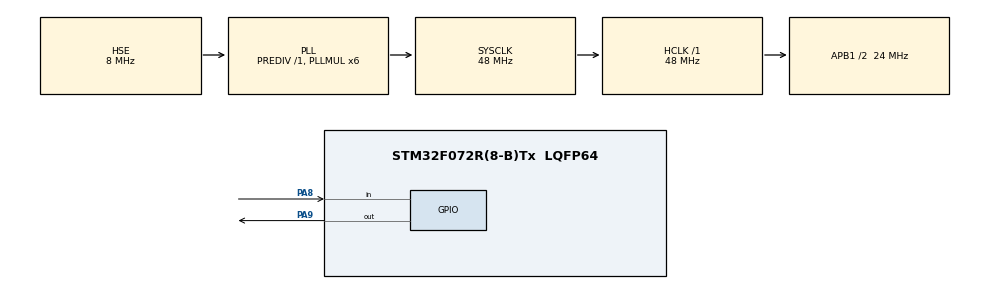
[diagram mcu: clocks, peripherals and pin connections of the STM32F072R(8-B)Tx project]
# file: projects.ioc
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Mcu.Family=STM32F0
Mcu.Name=STM32F072R(8-B)Tx
Mcu.Package=LQFP64
PA13.Mode=Serial_Wire
PA13.Signal=SYS_SWDIO
PA14.Mode=Serial_Wire
PA14.Signal=SYS_SWCLK
PA8.Signal=GPIO_Input
PA9.Signal=GPIO_Output
PF0-OSC_IN.Mode=HSE-External-Oscillator
PF0-OSC_IN.Signal=RCC_OSC_IN
PF1-OSC_OUT.Mode=HSE-External-Oscillator
PF1-OSC_OUT.Signal=RCC_OSC_OUT
ProjectManager.HeapSize=0x200
ProjectManager.StackSize=0x400
ProjectManager.TargetToolchain=MDK-ARM V5.32
RCC.AHBFreq_Value=48000000
RCC.APB1CLKDivider=RCC_HCLK_DIV2
RCC.APB1Freq_Value=24000000
RCC.APB1TimFreq_Value=48000000
RCC.HCLKFreq_Value=48000000
RCC.PLLMUL=RCC_PLL_MUL6
RCC.PLLSourceVirtual=RCC_PLLSOURCE_HSE
RCC.SYSCLKFreq_VALUE=48000000
RCC.SYSCLKSource=RCC_SYSCLKSOURCE_PLLCLK
TIM1.Prescaler=47
VP_TIM1_VS_ClockSourceINT.Mode=Internal
board=custom

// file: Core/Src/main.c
/* USER CODE BEGIN Header */
/**
  ******************************************************************************
  * @file           : main.c
  * @brief          : Main program body
  ******************************************************************************
  * @attention
  *
  * Copyright (c) 2024 STMicroelectronics.
  * All rights reserved.
  *
  * This software is licensed under terms that can be found in the LICENSE file
  * in the root directory of this software component.
  * If no LICENSE file comes with this software, it is provided AS-IS.
  *
  ******************************************************************************
  */
/* USER CODE END Header */
#include "main.h"

TIM_HandleTypeDef htim1;

/* USER CODE BEGIN PV */
#define trig GPIO_PIN_9
#define trigPort GPIOA
#define echo GPIO_PIN_8
#define echoPort GPIOA
uint32_t timems;
uint32_t Echo1 = 0;
uint32_t Echo2 = 0;
uint16_t Distance  = 0;  // cm
/* USER CODE END PV */

void SystemClock_Config(void);
static void MX_GPIO_Init(void);
static void MX_TIM1_Init(void);

/* USER CODE BEGIN 0 */
void LED_init(void) {
// Initialize PC8 and PC9 for LED's
RCC->AHBENR |= RCC_AHBENR_GPIOCEN;
GPIOC->MODER |= GPIO_MODER_MODER8_0 | GPIO_MODER_MODER9_0;
GPIOC->OTYPER &= ~(GPIO_OTYPER_OT_8 | GPIO_OTYPER_OT_9);
GPIOC->OSPEEDR &= ~((GPIO_OSPEEDR_OSPEEDR8_0 | GPIO_OSPEEDR_OSPEEDR8_1) |
(GPIO_OSPEEDR_OSPEEDR9_0 | GPIO_OSPEEDR_OSPEEDR9_1));
GPIOC->PUPDR &= ~((GPIO_PUPDR_PUPDR8_0 | GPIO_PUPDR_PUPDR8_1) |
(GPIO_PUPDR_PUPDR9_0 | GPIO_PUPDR_PUPDR9_1));
GPIOC->ODR &= ~(GPIO_ODR_8 | GPIO_ODR_9);
}
/* USER CODE END 0 */

int main(void)
{

  /* MCU Configuration--------------------------------------------------------*/

  /* Reset of all peripherals, Initializes the Flash interface and the Systick. */
	HAL_Init();

	// SystemClock_Config();

  /* USER CODE END Init */

  /* Configure the system clock */

  /* Initialize all configured peripherals */
  MX_GPIO_Init();
  MX_TIM1_Init();
	HAL_TIM_Base_Start(&htim1);
  HAL_GPIO_WritePin(trigPort, trig, GPIO_PIN_RESET);
	LED_init();

	GPIOA->MODER &= 0xFFFFC3FF; // clear PA4, PA5, PA6 bits
	GPIOA->MODER |= (1 << 8) | (1 << 10) | (1 << 12); // set PA4 to general purpose output mode
	GPIOA->ODR |= (1 << 4); // set PA4 high
  /* USER CODE END 2 */

  /* Infinite loop */
  /* USER CODE BEGIN WHILE */
  while (1)
  {
    HAL_GPIO_WritePin(trigPort, trig, GPIO_PIN_SET);  // pull the TRIG pin HIGH
    __HAL_TIM_SET_COUNTER(&htim1, 0);
    while (__HAL_TIM_GET_COUNTER (&htim1) < 10);  // wait for 10 us
    HAL_GPIO_WritePin(trigPort, trig, GPIO_PIN_RESET);  // pull the TRIG pin low
    timems = HAL_GetTick(); // used this to avoid infinite while loop  (for timeout)
    // wait for the echo pin to go high
    while (!(HAL_GPIO_ReadPin (echoPort, echo)) && timems + 10 >  HAL_GetTick());
    Echo1 = __HAL_TIM_GET_COUNTER (&htim1);

    timems = HAL_GetTick(); //to avoid infinite while loop

    // wait for the echo pin to go low
    while ((HAL_GPIO_ReadPin (echoPort, echo)) && timems + 50 > HAL_GetTick());
    Echo2 = __HAL_TIM_GET_COUNTER (&htim1);

    Distance = (Echo2-Echo1)* 0.034/2;

		if(Distance < 2){
			GPIOC->ODR ^= GPIO_ODR_9;
			//one direction pin to high, the other low
			GPIOA->ODR &= ~(1 << 5);
			GPIOA->ODR |= (1 << 4);

		} else {
			GPIOA->ODR &= ~(1 << 4);
			GPIOA->ODR |= (1 << 5);
		}
		//todo

    HAL_Delay(50);
    /* USER CODE END WHILE */

  }
}

void SystemClock_Config(void)
{
  RCC_OscInitTypeDef RCC_OscInitStruct = {0};
  RCC_ClkInitTypeDef RCC_ClkInitStruct = {0};

  /** Initializes the RCC Oscillators according to the specified parameters
  * in the RCC_OscInitTypeDef structure.
  */
  RCC_OscInitStruct.OscillatorType = RCC_OSCILLATORTYPE_HSE;
  RCC_OscInitStruct.HSEState = RCC_HSE_ON;
  RCC_OscInitStruct.PLL.PLLState = RCC_PLL_ON;
  RCC_OscInitStruct.PLL.PLLSource = RCC_PLLSOURCE_HSE;
  RCC_OscInitStruct.PLL.PLLMUL = RCC_PLL_MUL6;
  RCC_OscInitStruct.PLL.PREDIV = RCC_PREDIV_DIV1;
  if (HAL_RCC_OscConfig(&RCC_OscInitStruct) != HAL_OK)
  {
    Error_Handler();
  }

  /** Initializes the CPU, AHB and APB buses clocks
  */
  RCC_ClkInitStruct.ClockType = RCC_CLOCKTYPE_HCLK|RCC_CLOCKTYPE_SYSCLK
                              |RCC_CLOCKTYPE_PCLK1;
  RCC_ClkInitStruct.SYSCLKSource = RCC_SYSCLKSOURCE_PLLCLK;
  RCC_ClkInitStruct.AHBCLKDivider = RCC_SYSCLK_DIV1;
  RCC_ClkInitStruct.APB1CLKDivider = RCC_HCLK_DIV2;

  if (HAL_RCC_ClockConfig(&RCC_ClkInitStruct, FLASH_LATENCY_1) != HAL_OK)
  {
    Error_Handler();
  }
}

static void MX_TIM1_Init(void)
{

  TIM_ClockConfigTypeDef sClockSourceConfig = {0};
  TIM_MasterConfigTypeDef sMasterConfig = {0};

  htim1.Instance = TIM1;
  htim1.Init.Prescaler = 47;
  htim1.Init.CounterMode = TIM_COUNTERMODE_UP;
  htim1.Init.Period = 65535;
  htim1.Init.ClockDivision = TIM_CLOCKDIVISION_DIV1;
  htim1.Init.RepetitionCounter = 0;
  htim1.Init.AutoReloadPreload = TIM_AUTORELOAD_PRELOAD_DISABLE;
  if (HAL_TIM_Base_Init(&htim1) != HAL_OK)
  {
    Error_Handler();
  }
  sClockSourceConfig.ClockSource = TIM_CLOCKSOURCE_INTERNAL;
  if (HAL_TIM_ConfigClockSource(&htim1, &sClockSourceConfig) != HAL_OK)
  {
    Error_Handler();
  }
  sMasterConfig.MasterOutputTrigger = TIM_TRGO_RESET;
  sMasterConfig.MasterSlaveMode = TIM_MASTERSLAVEMODE_DISABLE;
  if (HAL_TIMEx_MasterConfigSynchronization(&htim1, &sMasterConfig) != HAL_OK)
  {
    Error_Handler();
  }

}

static void MX_GPIO_Init(void)
{
  GPIO_InitTypeDef GPIO_InitStruct = {0};

  /* GPIO Ports Clock Enable */
  __HAL_RCC_GPIOF_CLK_ENABLE();
  __HAL_RCC_GPIOA_CLK_ENABLE();

  /*Configure GPIO pin Output Level */
  HAL_GPIO_WritePin(GPIOA, GPIO_PIN_9, GPIO_PIN_RESET);

  /*Configure GPIO pin : PA8 */
  GPIO_InitStruct.Pin = GPIO_PIN_8;
  GPIO_InitStruct.Mode = GPIO_MODE_INPUT;
  GPIO_InitStruct.Pull = GPIO_NOPULL;
  HAL_GPIO_Init(GPIOA, &GPIO_InitStruct);

  /*Configure GPIO pin : PA9 */
  GPIO_InitStruct.Pin = GPIO_PIN_9;
  GPIO_InitStruct.Mode = GPIO_MODE_OUTPUT_PP;
  GPIO_InitStruct.Pull = GPIO_NOPULL;
  GPIO_InitStruct.Speed = GPIO_SPEED_FREQ_LOW;
  HAL_GPIO_Init(GPIOA, &GPIO_InitStruct);

}

void Error_Handler(void)
{
  __disable_irq();
  while (1)
  {
  }
}
